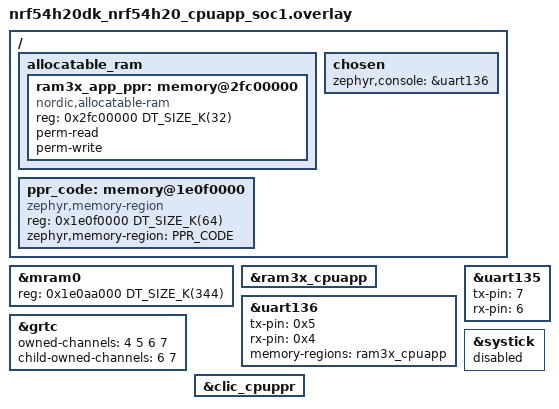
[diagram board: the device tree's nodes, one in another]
/*
 * Copyright (c) 2022 Nordic Semiconductor ASA
 *
 * SPDX-License-Identifier: LicenseRef-Nordic-5-Clause
 */

 /{
	allocatable_ram {
		#address-cells = <1>;
		#size-cells = <1>;

		/* Configure PPR memory region. Allow to use defined RAM3x
		 * region by App and cores owned by App.
		 */
		ram3x_app_ppr: memory@2fc00000 {
			compatible = "nordic,allocatable-ram";
			reg = <0x2fc00000 DT_SIZE_K(32)>;
			perm-read;
			perm-write;
		};
	};

	/* Configure PPR code region. Allow to execute from defined
	 * region by App and cores owned by App.
	 */
	ppr_code: memory@1e0f0000 {
		compatible = "zephyr,memory-region", "mmio-sram";
		reg = <0x1e0f0000 DT_SIZE_K(64)>;
		zephyr,memory-region = "PPR_CODE";
	};

	chosen {
		zephyr,console = &uart136;
	};
};

&mram0 {
	/* Expand to include PPR */
	reg = <0x1e0aa000 DT_SIZE_K(344)>;
};

/* ram3x_cpuapp buffer is used by App core UART driver. */
&ram3x_cpuapp {
	status = "okay";
};

&uart136 {
	status = "okay";
	tx-pin = < 0x5 >;
	rx-pin = < 0x4 >;
	memory-regions = <&ram3x_cpuapp>;
};

/* Configure PPR UART. */
&uart135 {
	status = "okay";
	tx-pin = <7>;
	rx-pin = <6>;
};

&grtc {
	status = "okay";
	/* Channels 4 and 5 are used by the app core itself, channels 6 and 7
	 * are owned by App but used by PPR.
	 */
	owned-channels = <4 5 6 7>;
	child-owned-channels = <6 7>;
};

/* Enable PPR clic so App could start PPR. */
&clic_cpuppr {
	status = "okay";
};

/* Disable systick for App core, GRTC is used as tick source. */
&systick {
	status = "disabled";
};
